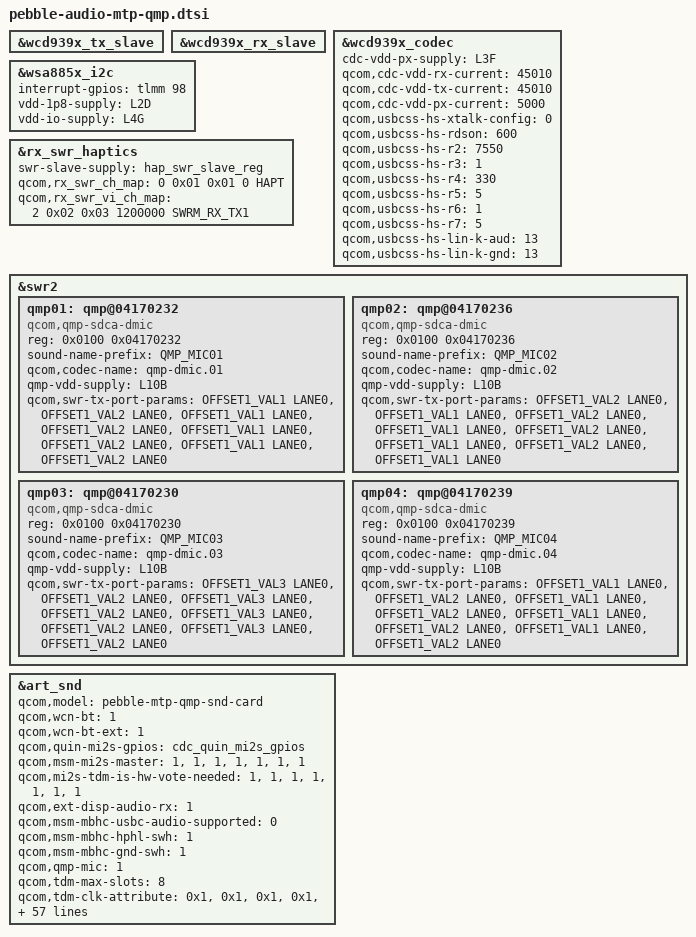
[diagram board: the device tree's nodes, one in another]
// SPDX-License-Identifier: BSD-3-Clause
/*
 * Copyright (c) Qualcomm Technologies, Inc. and/or its subsidiaries.
 */

/dts-v1/;
/plugin/;

#include "lpass-audio-cdc-1.0.dtsi"
#include "art-lpi.dtsi"
#include "lpass-audio-bt-swr.dtsi"
#include "lpass-cdc-gpio.dtsi"
#include "art-audio-lpass-reg.dtsi"
#include "wsa8855-i2c.dtsi"
#include "wcd.dtsi"

&wcd939x_tx_slave {
	status = "okay";
};

&wcd939x_rx_slave {
	status = "okay";
};

&wcd939x_codec {
	status = "okay";
	cdc-vdd-px-supply = <&L3F>;
	qcom,cdc-vdd-rx-current = <45010>;
	qcom,cdc-vdd-tx-current = <45010>;
	qcom,cdc-vdd-px-current = <5000>;
	/* 0 for digital crosstalk disabled,
	 * 1 for digital crosstalk with local sensed a-xtalk enabled, and
	 * 2 for digital crosstalk with remote sensed a-xtalk enabled.
	 */
	qcom,usbcss-hs-xtalk-config = <0>;
	qcom,usbcss-hs-rdson = <600>;
	qcom,usbcss-hs-r2 = <7550>;
	qcom,usbcss-hs-r3 = <1>;
	qcom,usbcss-hs-r4 = <330>;
	qcom,usbcss-hs-r5 = <5>;
	qcom,usbcss-hs-r6 = <1>;
	qcom,usbcss-hs-r7 = <5>;
	qcom,usbcss-hs-lin-k-aud = <13>;
	qcom,usbcss-hs-lin-k-gnd = <13>;
};


&wsa885x_i2c {
	interrupt-gpios = <&tlmm 98 GPIO_ACTIVE_HIGH>;
	vdd-1p8-supply = <&L2D>;
	vdd-io-supply = <&L4G>;
};

&rx_swr_haptics {
	status = "okay";
	swr-slave-supply = <&hap_swr_slave_reg>;
	qcom,rx_swr_ch_map = <0 0x01 0x01 0 HAPT>;
	qcom,rx_swr_vi_ch_map = <2 0x02 0x03 1200000 SWRM_RX_TX1>;
};

&swr2 {
	qmp01: qmp@04170232 {
		/*
		 * reg = <Class_partID[7:0]
		 * partID[15:8] manuID[7:0] manuID[15:8](version4bits_UniqueID4bits)
		 */
		reg = <0x0100 0x04170232>;
		compatible = "qcom,qmp-sdca-dmic";
		sound-name-prefix = "QMP_MIC01";
		qcom,codec-name = "qmp-dmic.01";
		qmp-vdd-supply = <&L10B>;
		qcom,swr-tx-port-params =
				<OFFSET1_VAL1 LANE0>, <OFFSET1_VAL2 LANE0>,
				<OFFSET1_VAL1 LANE0>, <OFFSET1_VAL2 LANE0>,
				<OFFSET1_VAL1 LANE0>, <OFFSET1_VAL2 LANE0>,
				<OFFSET1_VAL1 LANE0>, <OFFSET1_VAL2 LANE0>;
	};

	qmp02: qmp@04170236 {
		reg = <0x0100 0x04170236>;
		compatible = "qcom,qmp-sdca-dmic";
		sound-name-prefix = "QMP_MIC02";
		qcom,codec-name = "qmp-dmic.02";
		qmp-vdd-supply = <&L10B>;
		qcom,swr-tx-port-params =
				<OFFSET1_VAL2 LANE0>, <OFFSET1_VAL1 LANE0>,
				<OFFSET1_VAL2 LANE0>, <OFFSET1_VAL1 LANE0>,
				<OFFSET1_VAL2 LANE0>, <OFFSET1_VAL1 LANE0>,
				<OFFSET1_VAL2 LANE0>, <OFFSET1_VAL1 LANE0>;
	};

	qmp03: qmp@04170230 {
		reg = <0x0100 0x04170230>;
		compatible = "qcom,qmp-sdca-dmic";
		sound-name-prefix = "QMP_MIC03";
		qcom,codec-name = "qmp-dmic.03";
		qmp-vdd-supply = <&L10B>;
		qcom,swr-tx-port-params =
				<OFFSET1_VAL3 LANE0>, <OFFSET1_VAL2 LANE0>,
				<OFFSET1_VAL3 LANE0>, <OFFSET1_VAL2 LANE0>,
				<OFFSET1_VAL3 LANE0>, <OFFSET1_VAL2 LANE0>,
				<OFFSET1_VAL3 LANE0>, <OFFSET1_VAL2 LANE0>;
	};

	qmp04: qmp@04170239 {
		reg = <0x0100 0x04170239>;
		compatible = "qcom,qmp-sdca-dmic";
		sound-name-prefix = "QMP_MIC04";
		qcom,codec-name = "qmp-dmic.04";
		qmp-vdd-supply = <&L10B>;
		qcom,swr-tx-port-params =
				<OFFSET1_VAL1 LANE0>, <OFFSET1_VAL2 LANE0>,
				<OFFSET1_VAL1 LANE0>, <OFFSET1_VAL2 LANE0>,
				<OFFSET1_VAL1 LANE0>, <OFFSET1_VAL2 LANE0>,
				<OFFSET1_VAL1 LANE0>, <OFFSET1_VAL2 LANE0>;
	};
};

&art_snd {
	qcom,model = "pebble-mtp-qmp-snd-card";
	qcom,wcn-bt = <1>;
	qcom,wcn-bt-ext = <1>;
	qcom,quin-mi2s-gpios = <&cdc_quin_mi2s_gpios>;
	qcom,msm-mi2s-master = <1>, <1>, <1>, <1>, <1>, <1>, <1>;
	qcom,mi2s-tdm-is-hw-vote-needed = <1>, <1>, <1>, <1>, <1>, <1>, <1>;
	qcom,ext-disp-audio-rx = <1>;
	qcom,msm-mbhc-usbc-audio-supported = <0>;
	qcom,msm-mbhc-hphl-swh = <1>;
	qcom,msm-mbhc-gnd-swh = <1>;
	qcom,qmp-mic = <1>;
	qcom,tdm-max-slots = <8>;
	qcom,tdm-clk-attribute = <0x1>, <0x1>, <0x1>, <0x1>, <0x1>, <0x1>, <0x1>;
	qcom,mi2s-clk-attribute = <0x1>, <0x1>, <0x1>, <0x1>, <0x1>, <0x1>, <0x1>;
	qcom,audio-core-list = <0>, <1>;
	wcd939x-i2c-handle = <&wcd_usbss>;
	qcom,msm_audio_ssr_devs = <&audio_gpr>, <&lpi_tlmm>,
				  <&lpass_cdc>, <&lpass_bt_swr>;
	qcom,msm-mbhc-hs-mic-max-threshold-mv = <1670>;
	asoc-codec  = <&stub_codec>, <&lpass_cdc>,
				<&rx_swr_haptics>, <&wcd939x_codec>, <&qmp01>, <&qmp02>,
			<&qmp03>, <&qmp04>, <&wsa885x_i2c>;
	asoc-codec-names = "msm-stub-codec.1", "lpass-cdc",
				"swr-haptics", "wcd939x_codec", "qmp-dmic.01", "qmp-dmic.02",
				"qmp-dmic.03", "qmp-dmic.04", "wsa885x_i2c";
	qcom,audio-routing =
		"AMIC1", "Analog Mic1",
		"AMIC1", "MIC BIAS1",
		"AMIC2", "Analog Mic2",
		"AMIC2", "MIC BIAS2",
		"AMIC3", "Analog Mic3",
		"AMIC3", "MIC BIAS3",
		"AMIC4", "Analog Mic4",
		"AMIC4", "MIC BIAS3",
		"AMIC5", "Analog Mic5",
		"AMIC5", "MIC BIAS4",
		"VA AMIC1", "Analog Mic1",
		"VA AMIC1", "VA MIC BIAS1",
		"VA AMIC2", "Analog Mic2",
		"VA AMIC2", "VA MIC BIAS2",
		"VA AMIC3", "Analog Mic3",
		"VA AMIC3", "VA MIC BIAS3",
		"VA AMIC4", "Analog Mic4",
		"VA AMIC4", "VA MIC BIAS3",
		"VA AMIC5", "Analog Mic5",
		"VA AMIC5", "VA MIC BIAS4",
		"TX DMIC0", "Digital Mic0",
		"TX DMIC0", "MIC BIAS1",
		"TX DMIC1", "Digital Mic1",
		"TX DMIC1", "MIC BIAS3",
		"TX DMIC2", "Digital Mic2",
		"TX DMIC2", "MIC BIAS3",
		"TX DMIC3", "Digital Mic3",
		"TX DMIC3", "MIC BIAS1",
		"IN1_HPHL", "HPHL_OUT",
		"IN2_HPHR", "HPHR_OUT",
		"IN3_EAR", "AUX_OUT",
		"HAP_IN", "PCM_OUT",
		"RX_TX DEC0_INP", "TX DEC0 MUX",
		"RX_TX DEC1_INP", "TX DEC1 MUX",
		"RX_TX DEC2_INP", "TX DEC2 MUX",
		"RX_TX DEC3_INP", "TX DEC3 MUX",
		"TX SWR_INPUT", "WCD_TX_OUTPUT",
		"TX SWR_INPUT", "QMP_MIC01 NORMAL_OUTPUT",
		"TX SWR_INPUT", "QMP_MIC02 NORMAL_OUTPUT",
		"TX SWR_INPUT", "QMP_MIC03 NORMAL_OUTPUT",
		"TX SWR_INPUT", "QMP_MIC04 NORMAL_OUTPUT",
		"VA SWR_INPUT", "VA_SWR_CLK",
		"VA SWR_INPUT", "WCD_TX_OUTPUT",
		"VA SWR_INPUT", "QMP_MIC01 LP_OUTPUT",
		"VA SWR_INPUT", "QMP_MIC02 LP_OUTPUT",
		"VA SWR_INPUT", "QMP_MIC03 LP_OUTPUT",
		"VA SWR_INPUT", "QMP_MIC04 LP_OUTPUT",
		"VA SWR_INPUT", "QMP_MIC01 VA_NORMAL_OUTPUT",
		"VA SWR_INPUT", "QMP_MIC02 VA_NORMAL_OUTPUT",
		"VA SWR_INPUT", "QMP_MIC03 VA_NORMAL_OUTPUT",
		"VA SWR_INPUT", "QMP_MIC04 VA_NORMAL_OUTPUT",
		"VA_AIF1 CAP", "VA_SWR_CLK",
		"VA_AIF2 CAP", "VA_SWR_CLK",
		"VA_AIF3 CAP", "VA_SWR_CLK",
		"VA DMIC0", "Digital Mic0",
		"VA DMIC1", "Digital Mic1",
		"VA DMIC2", "Digital Mic2",
		"VA DMIC3", "Digital Mic3",
		"VA DMIC0", "VA MIC BIAS3",
		"VA DMIC1", "VA MIC BIAS3",
		"VA DMIC2", "VA MIC BIAS1",
		"VA DMIC3", "VA MIC BIAS1";
};
